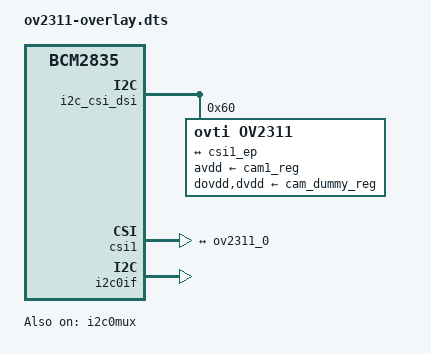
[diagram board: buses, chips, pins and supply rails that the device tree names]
// SPDX-License-Identifier: GPL-2.0-only
// Definitions for OV2311 camera module on VC I2C bus
/dts-v1/;
/plugin/;

#include <dt-bindings/gpio/gpio.h>

/{
	compatible = "brcm,bcm2835";

	i2c_frag: fragment@0 {
		target = <&i2c_csi_dsi>;
		__overlay__ {
			#address-cells = <1>;
			#size-cells = <0>;
			status = "okay";

			ov2311: ov2311@60 {
				compatible = "ovti,ov2311";
				reg = <0x60>;
				status = "okay";

				clocks = <&cam1_clk>;
				clock-names = "xvclk";

				avdd-supply = <&cam1_reg>;
				dovdd-supply = <&cam_dummy_reg>;
				dvdd-supply = <&cam_dummy_reg>;

				rotation = <0>;
				orientation = <2>;

				port {
					ov2311_0: endpoint {
						remote-endpoint = <&csi1_ep>;
						clock-lanes = <0>;
						data-lanes = <1 2>;
						link-frequencies =
							/bits/ 64 <400000000>;
					};
				};
			};
		};
	};

	csi_frag: fragment@1 {
		target = <&csi1>;
		csi: __overlay__ {
			status = "okay";
			brcm,media-controller;

			port {
				csi1_ep: endpoint {
					remote-endpoint = <&ov2311_0>;
					data-lanes = <1 2>;
				};
			};
		};
	};

	fragment@2 {
		target = <&i2c0if>;
		__overlay__ {
			status = "okay";
		};
	};

	fragment@3 {
		target = <&i2c0mux>;
		__overlay__ {
			status = "okay";
		};
	};

	clk_frag: fragment@4 {
		target = <&cam1_clk>;
		__overlay__ {
			status = "okay";
			clock-frequency = <24000000>;
		};
	};

	__overrides__ {
		rotation = <&ov2311>,"rotation:0";
		orientation = <&ov2311>,"orientation:0";
		media-controller = <&csi>,"brcm,media-controller?";
		cam0 = <&i2c_frag>, "target:0=",<&i2c_vc>,
		       <&csi_frag>, "target:0=",<&csi0>,
		       <&clk_frag>, "target:0=",<&cam0_clk>,
		       <&ov2311>, "clocks:0=",<&cam0_clk>,
		       <&ov2311>, "avdd-supply:0=",<&cam0_reg>;
	};
};
